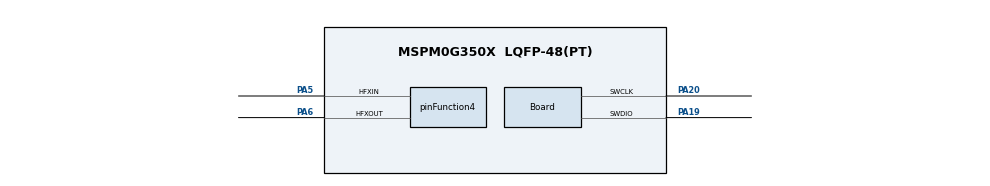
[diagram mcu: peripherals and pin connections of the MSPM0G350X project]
/**
 * @cliArgs --device "MSPM0G350X" --part "Default" --package "LQFP-48(PT)" --product "mspm0_sdk@2.02.00.05"
 * @versions {"tool":"1.21.1+3772"}
 */
scripting.excludeFromBuild("device_linker.cmd");
scripting.excludeFromBuild("device_linker.lds");
scripting.excludeFromBuild("device.opt");
scripting.excludeFromBuild("device.cmd.genlibs");
scripting.excludeFromBuild("device.lds.genlibs");

/**
 * Import the modules used in this configuration.
 */
const GPIO          = scripting.addModule("/ti/driverlib/GPIO", {}, false);
const GPIO1         = GPIO.addInstance();
const GPIO2         = GPIO.addInstance();
const SYSCTL        = scripting.addModule("/ti/driverlib/SYSCTL");
const SYSTICK       = scripting.addModule("/ti/driverlib/SYSTICK");
const ProjectConfig = scripting.addModule("/ti/project_config/ProjectConfig");

/**
 * Write custom configuration values to the imported modules.
 */
const divider6       = system.clockTree["PLL_CLK2X_DIV"];
divider6.divideValue = 4;

const divider9       = system.clockTree["UDIV"];
divider9.divideValue = 2;

const multiplier2         = system.clockTree["PLL_QDIV"];
multiplier2.multiplyValue = 4;

const mux4       = system.clockTree["EXHFMUX"];
mux4.inputSelect = "EXHFMUX_XTAL";

const mux8       = system.clockTree["HSCLKMUX"];
mux8.inputSelect = "HSCLKMUX_SYSPLL2X";

const mux12       = system.clockTree["SYSPLLMUX"];
mux12.inputSelect = "zSYSPLLMUX_HFCLK";

const pinFunction4                        = system.clockTree["HFXT"];
pinFunction4.enable                       = true;
pinFunction4.inputFreq                    = 40;
pinFunction4.peripheral.$assign           = "SYSCTL";
pinFunction4.peripheral.hfxInPin.$assign  = "PA5";
pinFunction4.peripheral.hfxOutPin.$assign = "PA6";

GPIO1.$name                          = "MSP";
GPIO1.associatedPins.create(2);
GPIO1.associatedPins[0].$name        = "LED_BLUE";
GPIO1.associatedPins[0].assignedPin  = "2";
GPIO1.associatedPins[0].assignedPort = "PORTB";
GPIO1.associatedPins[1].$name        = "LED_GREEN";
GPIO1.associatedPins[1].assignedPort = "PORTB";
GPIO1.associatedPins[1].assignedPin  = "3";

const Board                       = scripting.addModule("/ti/driverlib/Board", {}, false);
Board.peripheral.$assign          = "DEBUGSS";
Board.peripheral.swclkPin.$assign = "PA20";
Board.peripheral.swdioPin.$assign = "PA19";

GPIO2.$name                              = "BSP";
GPIO2.associatedPins[0].$name            = "KEY";
GPIO2.associatedPins[0].direction        = "INPUT";
GPIO2.associatedPins[0].internalResistor = "PULL_DOWN";
GPIO2.associatedPins[0].assignedPin      = "13";
GPIO2.associatedPins[0].assignedPort     = "PORTA";

SYSCTL.forceDefaultClkConfig = true;
SYSCTL.clockTreeEn           = true;

SYSTICK.periodEnable    = true;
SYSTICK.systickEnable   = true;
SYSTICK.interruptEnable = true;
SYSTICK.period          = 80000;

ProjectConfig.deviceSpin = "MSPM0G3507";

/**
 * Pinmux solution for unlocked pins/peripherals. This ensures that minor changes to the automatic solver in a future
 * version of the tool will not impact the pinmux you originally saw.  These lines can be completely deleted in order to
 * re-solve from scratch.
 */
GPIO1.associatedPins[0].pin.$suggestSolution = "PB2";
GPIO1.associatedPins[1].pin.$suggestSolution = "PB3";
GPIO2.associatedPins[0].pin.$suggestSolution = "PA13";
